# PIC18F45K22 register map
Vendor: Microchip
Architecture 18xxxx. Special function registers and configuration words.
Registers are 8-bit, read-write, no defined reset value unless marked. A register's access mark holds for its fields unless they carry their own. Addresses are absolute, and some are shared; only a register's first bit layout is shown; lines under a group give offsets from that group; [hi:lo] are bit positions; {n}, {i} and the like mark numbered series; 'fields as' and 'values as' point back to an identical list; <NAME> marks a mode.

## Further device data
pins=1: RE3/MCLR/Vpp; 2: RB6/IOC/PGC; 3: RB7/IOC/PGD

## SFR
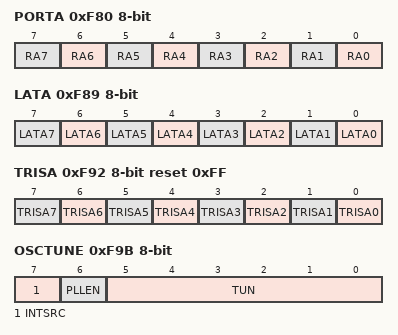
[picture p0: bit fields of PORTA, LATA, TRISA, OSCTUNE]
0xF80 PORTA — (power-on value xx0x0000)
  [n] RA{n} (n=0..7)
0xF89 LATA — (power-on value xxxxxxxx)
  [n] LATA{n} (n=0..7)
0xF92 TRISA reset 0xFF
  [n] TRISA{n} (n=0..7)
0xF9B OSCTUNE — (power-on value 00xxxxxx)
  [7] INTSRC, [6] PLLEN, [5:0] TUN
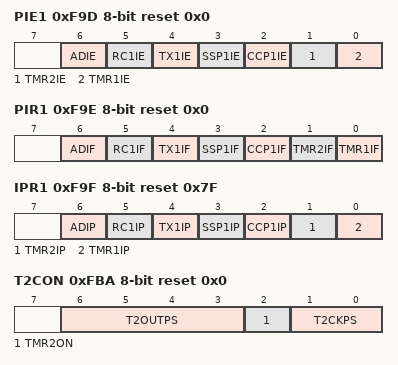
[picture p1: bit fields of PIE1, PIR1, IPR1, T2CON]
0xF9D PIE1 reset 0x0
  [6] ADIE
  [5] RC1IE — EUSART Receive Interrupt Enable
  [4] TX1IE — EUSART Transmit Interrupt Enable
  [3] SSP1IE
  [2] CCP1IE
  [1] TMR2IE
  [0] TMR1IE
0xF9E PIR1 reset 0x0
  [6] ADIF
  [5] RC1IF ro — EUSART Receive Interrupt Flag
  [4] TX1IF ro — EUSART Transmit Interrupt Flag
  [3] SSP1IF
  [2] CCP1IF
  [1] TMR2IF
  [0] TMR1IF
0xF9F IPR1 reset 0x7F
  [6] ADIP, [5] RC1IP, [4] TX1IP, [3] SSP1IP, [2] CCP1IP, [1] TMR2IP, [0] TMR1IP
0xFBA T2CON reset 0x0
  [6:3] T2OUTPS, [2] TMR2ON, [1:0] T2CKPS
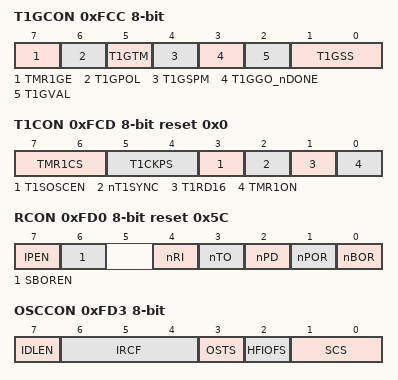
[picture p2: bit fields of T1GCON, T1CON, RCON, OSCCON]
0xFCC T1GCON — (power-on value 00000x00)
  [7] TMR1GE, [6] T1GPOL, [5] T1GTM, [4] T1GSPM, [3] T1GGO_nDONE, [2] T1GVAL ro, [1:0] T1GSS
0xFCD T1CON reset 0x0
  [7:6] TMR1CS, [5:4] T1CKPS, [3] T1SOSCEN, [2] nT1SYNC, [1] T1RD16, [0] TMR1ON
0xFCE TMR1L — (power-on value xxxxxxxx)
0xFCF TMR1H — (power-on value xxxxxxxx)
0xFD0 RCON reset 0x5C
  [7] IPEN, [6] SBOREN, [4] nRI, [3] nTO ro, [2] nPD ro, [1] nPOR, [0] nBOR
0xFD3 OSCCON — (power-on value 0110q000)
  [7] IDLEN, [6:4] IRCF, [3] OSTS ro, [2] HFIOFS ro, [1:0] SCS
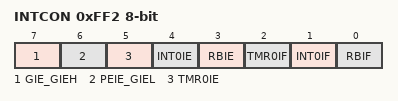
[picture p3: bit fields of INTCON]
0xFF2 INTCON — (power-on value 0000000x)
  [7] GIE_GIEH, [6] PEIE_GIEL, [5] TMR0IE, [4] INT0IE, [3] RBIE, [2] TMR0IF, [1] INT0IF, [0] RBIF
